# SPC1068 register map
File version: 20180100_70611510
CPU: CM3 r2p1, little endian, MPU, no FPU, 4 interrupt priority bits
Registers are 32-bit, read-write, reset 0x0 unless marked. A register's access mark holds for its fields unless they carry their own. Offsets are from the block's base; [hi:lo] are bit positions; {n}, {i} and the like mark numbered series; 'fields as' and 'values as' point back to an identical list; <NAME> marks a mode.

## CLOCK — Split from GLOBAL
Base 0x4000B000
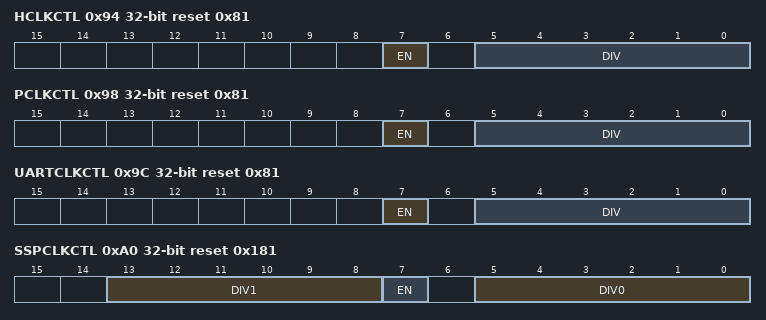
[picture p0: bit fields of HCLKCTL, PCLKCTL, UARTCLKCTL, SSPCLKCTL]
0x94 HCLKCTL reset 0x81 — HCLK Control Register
  [7] EN — Clock output enable
    0=DISABLE (Disable clock output); 1=ENABLE (Enable clock output)
  [5:0] DIV — Clock dividing ratio
0x98 PCLKCTL reset 0x81 — PCLK Control Register
  fields as HCLKCTL
0x9C UARTCLKCTL reset 0x81 — UART Clock Control Register
  fields as HCLKCTL
0xA0 SSPCLKCTL reset 0x181 — SSP Clock Control Register
  [13:8] DIV1 — Clock dividing ratio for the 2nd divider
  [7] EN — Clock output enable
    values as HCLKCTL.EN
  [5:0] DIV0 — Clock dividing ratio for the 1st divider
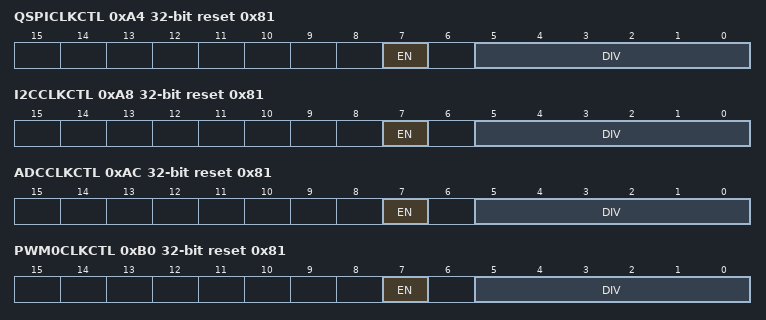
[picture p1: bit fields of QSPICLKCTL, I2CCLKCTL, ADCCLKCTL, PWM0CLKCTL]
0xA4 QSPICLKCTL reset 0x81 — QSPI Clock Control Register
  fields as HCLKCTL
0xA8 I2CCLKCTL reset 0x81 — I2C Clock Control Register
  fields as HCLKCTL
0xAC ADCCLKCTL reset 0x81 — ADC Clock Control Register
  fields as HCLKCTL
0xB0 PWM0CLKCTL reset 0x81 — PWM0 Clock Control Register
  fields as HCLKCTL
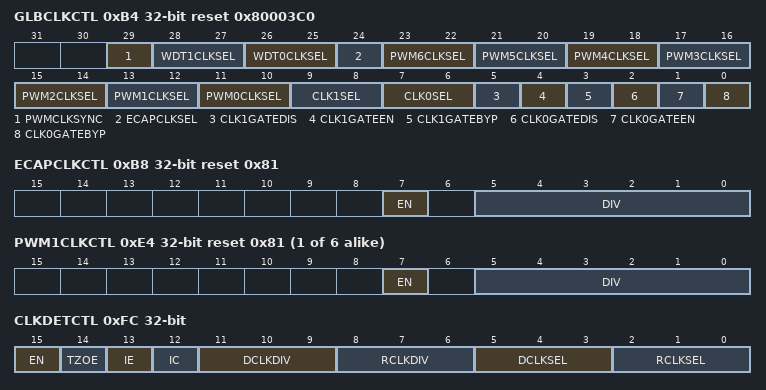
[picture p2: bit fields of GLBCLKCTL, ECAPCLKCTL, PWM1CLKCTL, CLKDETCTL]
0xB4 GLBCLKCTL reset 0x80003C0 — Global Clock Control Register
  [29] PWMCLKSYNC wo — PWM clock synchronization
    0=NO_EFFECT (Write a 0 has no effect); 1=ENABLE (Write a 1 will issue a PWM clock synchronization. This bit is self-cleared.)
  [28:27] WDT1CLKSEL — WDT1CLK selection
    0=RCO0 (CLK_RCO0); 1=RCO1 (CLK_RCO1); 2=PLL (CLK_PLL); 3=XO (CLK_XO)
  [26:25] WDT0CLKSEL — WDT0CLK selection
    values as WDT1CLKSEL
  [24] ECAPCLKSEL — ECAPCLK selection
    0=CLK1; 1=CLK0
  [2n+11:2n+10] PWM{n}CLKSEL (n=0..6) — PWM{n}CLK selection
    0=CLK1; 1=PWM (CLK_PWM); 2=CLK0
  [9:8] CLK1SEL — CLK1 selection
    0=XO (CLK_XO); 2=PLL (CLK_PLL); 3=RCO1 (CLK_RCO1)
  [7:6] CLK0SEL — CLK0 selection
    0=XO (CLK_XO); 2=PLL (CLK_PLL); 3=RCO0 (CLK_RCO0)
  [5] CLK1GATEDIS wo — Disable CLK1 gating
    0=NO_EFFECT (Write a 0 has no effect); 1=DISABLE_CLK1_GATE (Write a 1 will issue a pulse to disable CLK1 gating so that CLK1 will be on. This bit is self-cleared)
  [4] CLK1GATEEN wo — Enable CLK1 gating
    0=NO_EFFECT (Write a 0 has no effect); 1=ENABLE_CLK1_GATE (Write a 1 will issue a pulse to enable CLK1 gating so that CLK1 will be off. This bit is self-cleared)
  [3] CLK1GATEBYP — Bypass CLK1 gating
    0=DISABLE (Activate the CLK1 gating logic so CLK1 can be on/off by writing 1 to CLK1GATEDIS or CLK1GATEEN); 1=ENABLE (Bypass the CLK1 gating logic so that CLK1 is always on)
  [2] CLK0GATEDIS wo — Disable CLK0 gating
    0=NO_EFFECT (Write a 0 has no effect); 1=DISABLE_CLK0_GATE (Write a 1 will issue a pulse to disable CLK0 gating so that CLK0 will be on. This bit is self-cleared)
  [1] CLK0GATEEN wo — Enable CLK0 gating
    0=NO_EFFECT (Write a 0 has no effect); 1=ENABLE_CLK0_GATE (Write a 1 will issue a pulse to enable CLK0 gating so that CLK0 will be off. This bit is self-cleared)
  [0] CLK0GATEBYP — Bypass CLK0 gating
    0=DISABLE (Activate the CLK0 gating logic so CLK0 can be on/off by writing 1 to CLK0GATEDIS or CLK0GATEEN); 1=ENABLE (Bypass the CLK0 gating logic so that CLK0 is always on)
0xB8 ECAPCLKCTL reset 0x81 — ECAP Clock Control Register
  fields as HCLKCTL
0xC0 DGCLKCTL — De-glitch Clock Control Register
  [2:0] DIV — De-glitch clock dividing ratio from PCLK
    0=Divide by 1; 1=Divide by 2; 2=Divide by 4; 3=Divide by 8; 4=Divide by 16; 5=Divide by 32; 6=Divide by 64; 7=Divide by 128
{0xE0+4i} PWM{i}CLKCTL reset 0x81 (i=1..6) — PWM{i} Clock Control Register
  fields as HCLKCTL
0xFC CLKDETCTL — Clock Detection Control Register
  [15] EN — Clock detection enable. When disabled, the interrupts and the clock error events will be cleared
    0=DISABLE (Disable clock detection); 1=ENABLE (Enable clock detection)
  [14] TZOE — Clock error trip-zone event enable. This bit does not affect internal clock error status. If clock error happened during the period this bit is set to 0, a trip-zone event will be issued immediately when this bit is set to 1
    0=DISABLE (Disable clock error trip-zone event); 1=ENABLE (Enable clock error trip-zone event)
  [13] IE — Clock detection interrupt enable. When enabled, an interrupt will be generated at the end of a clock detect cycle
    0=DISABLE (Disable clock detection interrupt); 1=ENABLE (Enable clock detection interrupt)
  [12] IC wo — Clock detection interrupt clear
    1=CLEAR (Write 1 will clear the interrupt event. This bit is self cleared to 0)
  [11:9] DCLKDIV — DCLK dividing ratio
    values as DGCLKCTL.DIV
  [8:6] RCLKDIV — MCLK dividing ratio
    values as DGCLKCTL.DIV
  [5:3] DCLKSEL — Detected clock select
    0=RCO0 (CLK_RCO0); 1=RCO1 (CLK_RCO1); 2=XO (CLK_XO); 3=PLL (CLK_PLL); 4=PWM (CLK_PWM)
  [2:0] RCLKSEL — Master clock select
    values as DCLKSEL
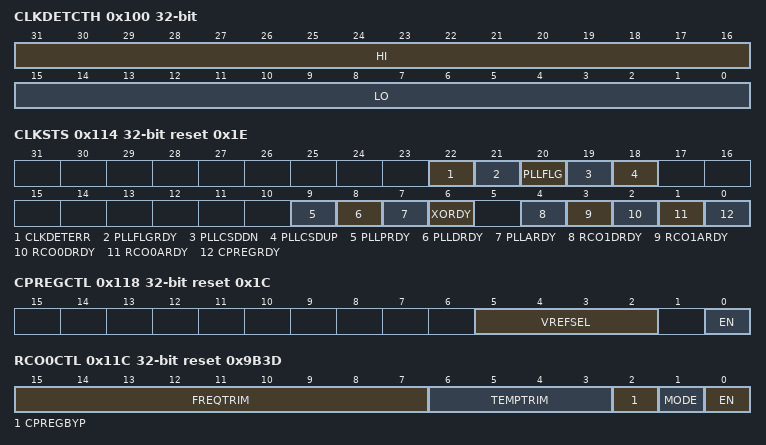
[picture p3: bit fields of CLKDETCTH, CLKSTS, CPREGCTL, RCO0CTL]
0x100 CLKDETCTH — Clock Detection Counter Threshold Register
  [31:16] HI — Upper counter threshold for clock detect. If the final counter value > HI, a trip-zone event will be generated for PWM
  [15:0] LO — Lower counter threshold for clock detect. If the final counter value < LO, a trip-zone event will be generated for PWM
0x104 CLKDETCNT ro — Clock Detection Counter Register
  [15:0] VAL — Final counter value of the clock detect
0x114 CLKSTS ro reset 0x1E — Clock Status Register
  [22] CLKDETERR — Clock error indicator from the clock detector
    0=NOT_OCCUR (Clock is correct for last detection); 1=OCCUR (Clock is error for last detection)
  [21] PLLFLGRDY — PLL frequency calibration flag ready indicator
    0=NOT_READY (PLLFLG is invalid); 1=READY (PLLFLG is valid)
  [20] PLLFLG — PLL frequency calibration flag
    0=TOO_SLOW (VCO in PLL is too slow); 1=TOO_FAST (VCO in PLL is too fast)
  [19] PLLCSDDN — PLL down-cycle-slip detection status. Once it is 1, this bit keeps as 1 until PLLCTL0.CSDEN=0 or PLLCTL0.CSDRST=1
    0=NOT_DETECTED (Down-cycle-slip is not detected); 1=DETECTED (Down-cycle-slip is detected since feedback divider output is too fast)
  [18] PLLCSDUP — PLL up-cycle-slip detection status. Once it is 1, this bit keeps as 1 until PLLCTL10.CSDEN=0 or PLLCTL0.CSDRST=1
    0=NOT_DETECTED (Up-cycle-slip is not detected); 1=DETECTED (Up-cycle-slip is detected since feedback divider output is too fast)
  [9] PLLPRDY — PLL PWM clock ready indicator
    0=NOT_READY; 1=READY
  [8] PLLDRDY — PLL digital clock ready indicator
    0=NOT_READY; 1=READY
  [7] PLLARDY — PLL analog clock ready indicator
    0=NOT_READY; 1=READY
  [6] XORDY — XO clock ready indicator
    0=NOT_READY; 1=READY
  [4] RCO1DRDY — RCO1 digital clock ready indicator
    0=NOT_READY; 1=READY
  [3] RCO1ARDY — RCO1 analog clock ready indicator
    0=NOT_READY; 1=READY
  [2] RCO0DRDY — RCO0 digital clock ready indicator
    0=NOT_READY; 1=READY
  [1] RCO0ARDY — RCO0 analog clock ready indicator
    0=NOT_READY; 1=READY
  [0] CPREGRDY — CPREG ready indicator
    0=NOT_READY; 1=READY
0x118 CPREGCTL reset 0x1C — Charge-pump Regulator Control Register
  [5:2] VREFSEL — Reference voltage select
    0=1dot13_V (1.13V); 1=1dot14_V (1.14V); 2=1dot15_V (1.15V); 3=1dot16_V (1.16V); 4=1dot17_V (1.17V); 5=1dot18_V (1.18V); 6=1dot19_V (1.19V); 7=1dot20_V (1.20V); 8=1dot21_V (1.21V); 9=1dot22_V (1.22V); 10=1dot23_V (1.23V); 11=1dot24_V (1.24V); 12=1dot25_V (1.25V); 13=1dot26_V (1.26V); 14=1dot27_V (1.27V); 15=1dot28_V (1.28V)
  [0] EN — Charge-pump regulator enable
    0=DISABLE; 1=ENABLE
0x11C RCO0CTL reset 0x9B3D — RCO0 Control Register
  [15:7] FREQTRIM — RCO0 frequency trimming. Frequency increases for larger code
  [6:3] TEMPTRIM — RCO0 frequency temperature trimming. Frequency increases with temperature faster for larger trim code
  [2] CPREGBYP — Bypass internal 1.2V regulator
    0=DISABLE (Connect 1.2V RCO1 gates to internal 1.2V regulator); 1=ENABLE (Connect 1.2V RCO1 gates to digital 1.2V power rail)
  [1] MODE — RCO0 mode
    0=24MHZ; 1=48MHZ
  [0] EN — RCO0 enable
    0=DISABLE; 1=ENABLE
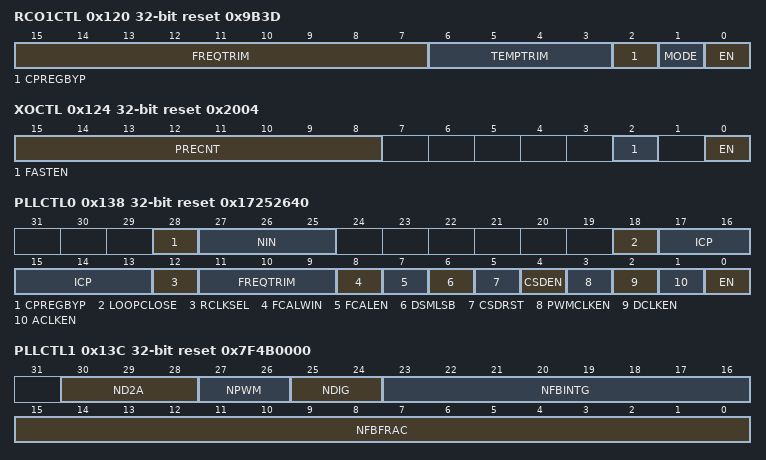
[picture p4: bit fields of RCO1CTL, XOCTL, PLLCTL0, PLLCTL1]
0x120 RCO1CTL reset 0x9B3D — RCO1 Control Register
  [15:7] FREQTRIM — RCO1 frequency trimming. Frequency increases for larger code
  [6:3] TEMPTRIM — RCO1 frequency temperature trimming. Frequency increases with temperature faster for larger trim code
  [2] CPREGBYP — Bypass internal 1.2V regulator
    values as RCO0CTL.CPREGBYP
  [1] MODE — RCO1 mode
    0=24MHZ; 1=48MHZ
  [0] EN — RCO1 enable
    0=DISABLE; 1=ENABLE
0x124 XOCTL reset 0x2004 — Crystal Oscillator Control Register
  [15:8] PRECNT — Pre-counted target value before XO clock is regarded as ready: Target = 1024 * PRECNT
  [2] FASTEN — Enable noise injection for fast startup
    0=DISABLE; 1=ENABLE
  [0] EN — Crystal oscillator clock enable
    0=DISABLE; 1=ENABLE
0x138 PLLCTL0 reset 0x17252640 — PLL Control Register 0
  [28] CPREGBYP — Bypass internal 1.2V regulator for PLL
    values as RCO0CTL.CPREGBYP
  [27:25] NIN — PLL input clock dividing ratio (Fin/Fpfd)
    1=Set to 1 if Fin(MHz) is in [4, 8]: Fin/Fpfd=1; 2=Set to 2 if Fin(MHz) is in (8, 16]: Fin/Fpfd=2; 3=Set to 3 if Fin(MHz) is in (16, 24]: Fin/Fpfd=3; 4=Set to 4 if Fin(MHz) is in (24, 32]: Fin/Fpfd=4; 5=Set to 5 if Fin(MHz) is in (32, 40]: Fin/Fpfd=5; 6=Set to 6 if Fin(MHz) is in (40, 48]: Fin/Fpfd=6; 7=Set to 1 if Fin(MHz) is in (48, 56]: Fin/Fpfd=7
  [18] LOOPCLOSE — PLL mode
    0=OPEN_LOOP; 1=CLOSE_LOOP
  [17:13] ICP — PLL charge pump setting. Must be set to NFB/(12-FREQTRIM), where NFB is the PLL feedback factor
  [12] RCLKSEL — PLL reference clock select
    0=RCO0 (CLK_RCO0 (RC oscillator 0)); 1=XO (CLK_XO (Crystal oscillator))
  [11:9] FREQTRIM — PLL frequency trimming. VCO free-run frequency increases with larger code
  [8] FCALWIN — PLL frequency calibration time window. For each calibration cycle, keep it as 1 until FCALRDY=1 and release it as 0
    0=DISABLE (Window is disabled); 1=ENABLE (Window is enabled)
  [7] FCALEN — PLL frequency calibration enable
    0=DISABLE; 1=ENABLE
  [6] DSMLSB — LSB dithering method for delta-sigma divider
    0=KEEP_1 (Keep as 1); 1=USE_RANDOM_BINARY (Use 7-th order pseudo-random binary sequence)
  [5] CSDRST — Reset PLL cycle slip detection output
    0=RELEASE (Release the reset); 1=RESET
  [4] CSDEN — PLL cycle slip detection enable
    0=DISABLE; 1=ENABLE
  [3] PWMCLKEN — PLL PWM clock output enable
    0=DISABLE; 1=ENABLE
  [2] DCLKEN — PLL digital clock output enable
    0=DISABLE; 1=ENABLE
  [1] ACLKEN — PLL analog clock output enable
    0=DISABLE; 1=ENABLE
  [0] EN — PLL enable
    0=DISABLE; 1=ENABLE
0x13C PLLCTL1 reset 0x7F4B0000 — PLL Control Register 1
  [30:28] ND2A — Digital clock to analog clock dividing ratio (FDIG/FANA)
    0=Divide by 4; 1=Divide by 8; 2=Divide by 16; 3=Divide by 32; 4=Divide by 64; 5=Divide by 128; 6=Divide by 256; 7=Divide by 512
  [27:26] NPWM — VCO to PWM clock dividing ratio (FVCO/FPWM)
    {v}=Divide by {v+1} (v=0..3)
  [25:24] NDIG — VCO to digital clock dividing ratio (FVCO/FDIG)
    {v}=Divide by {v+1} (v=0..3)
  [23:16] NFBINTG — Integral part of feedback dividing ratio. NFB (Feedback dividing ratio) = NFBINTG + NFBFRAC/65536
  [15:0] NFBFRAC — Fractional part of feedback dividing ratio. NFB (Feedback dividing ratio) = NFBINTG + NFBFRAC/65536
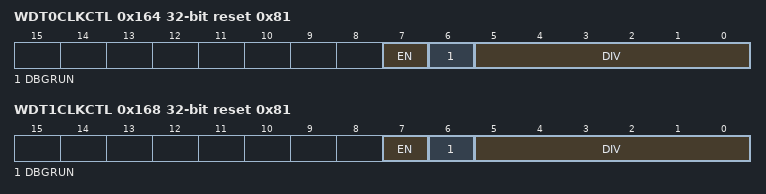
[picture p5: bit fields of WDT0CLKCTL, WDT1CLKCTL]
0x164 WDT0CLKCTL reset 0x81 — WDT0 Clock Control Register
  [7] EN — Clock output enable
    values as HCLKCTL.EN
  [6] DBGRUN — WDT0 clock keeps running when CPU is halted. Recommend setting this bit to 0 only when in debug and setting this bit to 1 in normal operation. . Note: Debug operation and CPU fault exceptions both can cause CPU halted.
    0=DISABLE (WDT0 clock does not run when CPU is halted); 1=ENABLE (WDT0 clock runs even when CPU is halted)
  [5:0] DIV — Clock dividing ratio
0x168 WDT1CLKCTL reset 0x81 — WDT1 Clock Control Register
  [7] EN — Clock output enable
    values as HCLKCTL.EN
  [6] DBGRUN — WDT1 clock keeps running when CPU is halted. Recommend setting this bit to 0 only when in debug and setting this bit to 1 in normal operation. . Note: Debug operation and CPU fault exceptions both can cause CPU halted.
    0=DISABLE (WDT1 clock does not run when CPU is halted); 1=ENABLE (WDT1 clock runs even when CPU is halted)
  [5:0] DIV — Clock dividing ratio
